# FM33FK5XX register map
File version: 1.0
CPU: Cortex-M33 r1p0, little endian, MPU, FPU, 3 interrupt priority bits
Registers are 32-bit, read-write, reset 0x0 unless marked. A register's access mark holds for its fields unless they carry their own. Offsets are from the block's base; [hi:lo] are bit positions; {n}, {i} and the like mark numbered series.

## FDCAN — FDCAN module information
Base 0x40019800
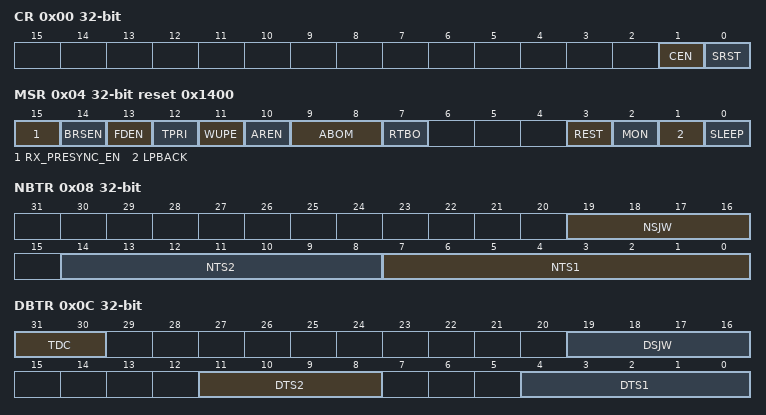
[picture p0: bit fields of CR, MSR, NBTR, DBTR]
0x00 CR — FDCANControlRegister
  [1] CEN — CEN field description
  [0] SRST — SRST field description
0x04 MSR reset 0x1400 — FDCANmodeselectregister
  [15] RX_PRESYNC_EN — RX_PRESYNC_EN field description
  [14] BRSEN — BRSEN field description
  [13] FDEN — FDEN field description
  [12] TPRI — TPRI field description
  [11] WUPE — WUPE field description
  [10] AREN — AREN field description
  [9:8] ABOM — ABOM field description
  [7] RTBO — RTBO field description
  [3] REST — REST field description
  [2] MON — MON field description
  [1] LPBACK — LPBACK field description
  [0] SLEEP — SLEEP field description
0x08 NBTR — FDCANNominalBitTimingRegister
  [19:16] NSJW — NSJW field description
  [14:8] NTS2 — NTS2 field description
  [7:0] NTS1 — NTS1 field description
0x0C DBTR — FDCANDataBitTimingRegister
  [31:30] TDC — TDC field description
  [19:16] DSJW — DSJW field description
  [11:8] DTS2 — DTS2 field description
  [4:0] DTS1 — DTS1 field description
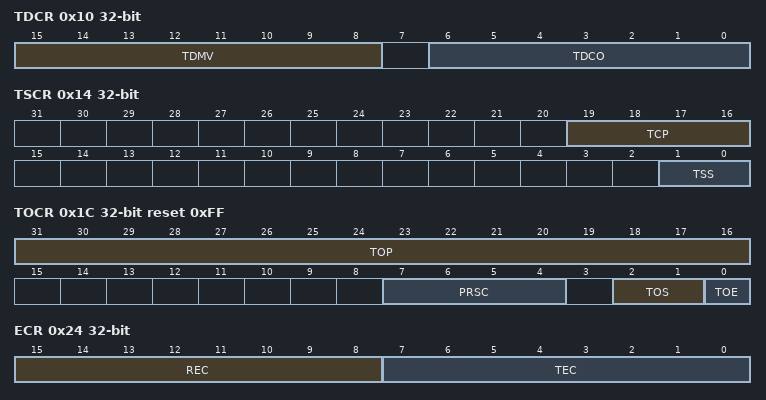
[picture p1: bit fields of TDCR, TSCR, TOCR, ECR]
0x10 TDCR — FDCANTransmissionDelayCompensationRegister
  [15:8] TDMV — TDMV field description
  [6:0] TDCO — TDCO field description
0x14 TSCR — FDCANTimeStampConfigRegister
  [19:16] TCP — TCP field description
  [1:0] TSS — TSS field description
0x18 TSVR — FDCANTimeStampValueRegister
  [15:0] TSV — TSV field description
0x1C TOCR reset 0xFF — FDCANTimeOutConfigRegister
  [31:16] TOP — TOP field description
  [7:4] PRSC — PRSC field description
  [2:1] TOS — TOS field description
  [0] TOE — TOE field description
0x20 TOVR reset 0xFFFF — FDCANTimeOutValueRegister
  [15:0] TOV — TOV field description
0x24 ECR ro — FDCANErrorCounterRegister
  [15:8] REC — REC field description
  [7:0] TEC — TEC field description
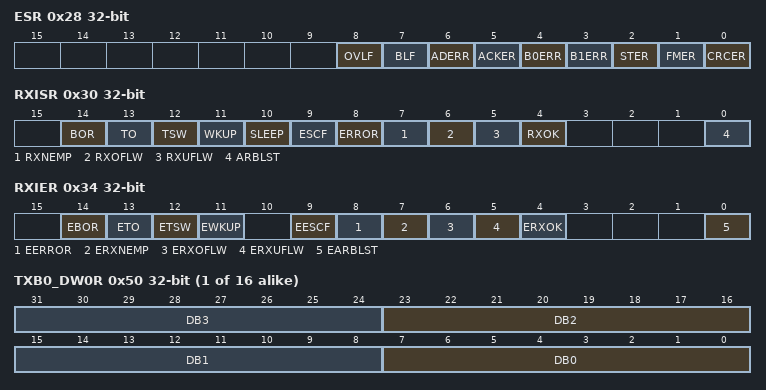
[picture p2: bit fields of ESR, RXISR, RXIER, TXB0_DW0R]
0x28 ESR — FDCANErrorStatusRegister
  [8] OVLF — OVLF field description
  [7] BLF — BLF field description
  [6] ADERR — ADERR field description
  [5] ACKER — ACKER field description
  [4] B0ERR — B0ERR field description
  [3] B1ERR — B1ERR field description
  [2] STER — STER field description
  [1] FMER — FMER field description
  [0] CRCER — CRCER field description
0x30 RXISR ro — FDCANInterruptStatusRegister
  [14] BOR — BOR field description
  [13] TO — TO field description
  [12] TSW — TSW field description
  [11] WKUP — WKUP field description
  [10] SLEEP — SLEEP field description
  [9] ESCF — ESCF field description
  [8] ERROR — ERROR field description
  [7] RXNEMP — RXNEMP field description
  [6] RXOFLW — RXOFLW field description
  [5] RXUFLW — RXUFLW field description
  [4] RXOK — RXOK field description
  [0] ARBLST — ARBLST field description
0x34 RXIER — FDCANInterruptEnableRegister
  [14] EBOR — EBOR field description
  [13] ETO — ETO field description
  [12] ETSW — ETSW field description
  [11] EWKUP — EWKUP field description
  [9] EESCF — EESCF field description
  [8] EERROR — EERROR field description
  [7] ERXNEMP — ERXNEMP field description
  [6] ERXOFLW — ERXOFLW field description
  [5] ERXUFLW — ERXUFLW field description
  [4] ERXOK — ERXOK field description
  [0] EARBLST — EARBLST field description
0x40 TXFSR ro
  [1:0] TXFWL — TXFWL field description
0x44 RXFSR ro
  [2:0] Water_lvl — Water_lvl field description
{0x48+0x48*i} TXB{i}_IDR wo (i=0..2) — FDCANTransmitBuffer{i}IDRegister
  [31:0] IDR — IDR field description
{0x4C+0x48*i} TXB{i}_DLCR wo (i=0..2) — FDCANTransmitBuffer{i}DLCRegister
  [3:0] DLC — DLC field description
{0x50+4i} TXB0_DW{i}R wo (i=0..15) — FDCANTransmitBuffer0DataWordRegistery) y=0~15
  [8n+7:8n] DB{n} (n=0..3) — DB{n} field description
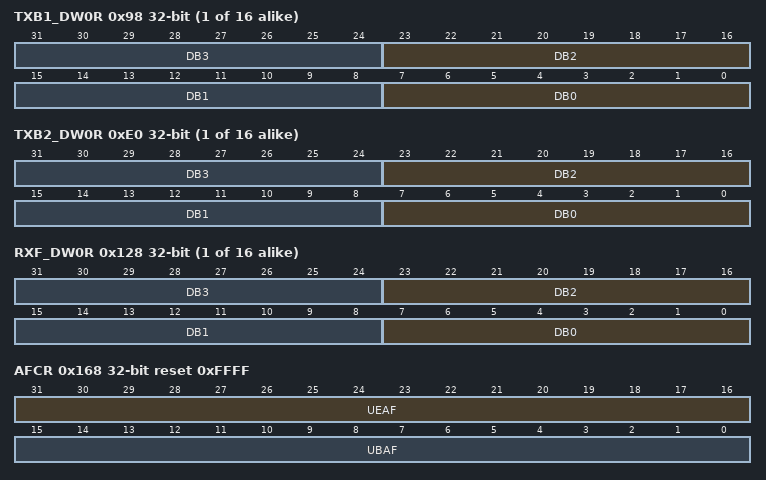
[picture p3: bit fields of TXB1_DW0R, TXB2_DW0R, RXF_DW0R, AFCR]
{0x98+4i} TXB1_DW{i}R wo (i=0..15) — FDCANTransmitBuffer1DataWordRegistery) y=0~15
  [8n+7:8n] DB{n} (n=0..3) — DB{n} field description
{0xE0+4i} TXB2_DW{i}R wo (i=0..15) — FDCANTransmitBuffer2DataWordRegistery) y=0~15
  [8n+7:8n] DB{n} (n=0..3) — DB{n} field description
0x120 RXF_IDR wo — FDCANReceiveFIFOIDRegister
  [31:0] IDR — IDR field description
0x124 RXF_DLCR wo — FDCANReceiveFIFODLCRegister
  [3:0] DLC — DLC field description
{0x128+4i} RXF_DW{i}R wo (i=0..15) — FDCANReceiveFIFODataWordRegistery) y=0~15
  [8n+7:8n] DB{n} (n=0..3) — DB{n} field description
0x168 AFCR reset 0xFFFF — FDCANAcceptanceFilterControlRegister
  [31:16] UEAF — UEAF field description
  [15:0] UBAF — UBAF field description
{0x16C+4i} AFBIR{i} (i=0..15) — FDCANAcceptanceFilterBasicIDRegister
  [31:0] BIR — BIR field description
{0x1AC+8i} AFEIR{i}F0 (i=0..15) — FDCANAcceptanceFilterExtendedIDF0Register
  [31:0] EIR — EIR field description
